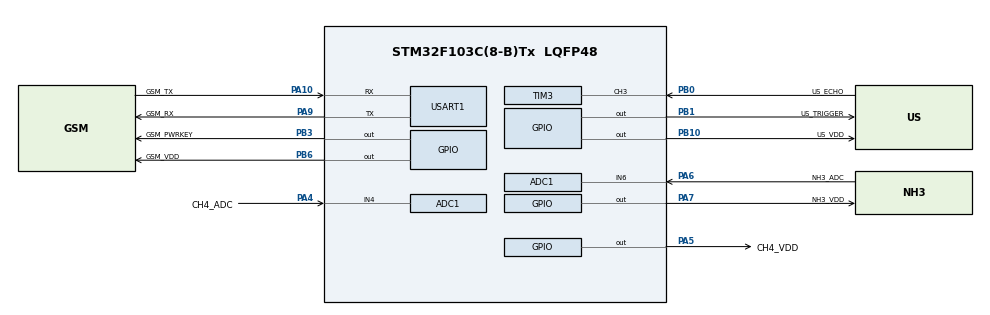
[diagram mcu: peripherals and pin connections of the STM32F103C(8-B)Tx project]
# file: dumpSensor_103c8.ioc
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ADC1.Channel-0\#ChannelRegularConversion=ADC_CHANNEL_6
ADC1.Channel-1\#ChannelRegularConversion=ADC_CHANNEL_4
ADC1.Channel-2\#ChannelRegularConversion=ADC_CHANNEL_TEMPSENSOR
ADC1.ContinuousConvMode=ENABLE
ADC1.NbrOfConversion=3
ADC1.NbrOfConversionFlag=1
ADC1.Rank-0\#ChannelRegularConversion=1
ADC1.Rank-1\#ChannelRegularConversion=2
ADC1.Rank-2\#ChannelRegularConversion=3
ADC1.SamplingTime-0\#ChannelRegularConversion=ADC_SAMPLETIME_71CYCLES_5
ADC1.SamplingTime-1\#ChannelRegularConversion=ADC_SAMPLETIME_71CYCLES_5
ADC1.SamplingTime-2\#ChannelRegularConversion=ADC_SAMPLETIME_41CYCLES_5
ADC1.master=1
Mcu.Family=STM32F1
Mcu.Name=STM32F103C(8-B)Tx
Mcu.Package=LQFP48
NVIC.PriorityGroup=NVIC_PRIORITYGROUP_4
NVIC.TIM3_IRQn=true\:0\:0\:false\:false\:true\:true\:true
NVIC.TIM4_IRQn=true\:0\:0\:false\:false\:true\:true\:true
NVIC.USART1_IRQn=true\:0\:0\:false\:false\:true\:true\:true
PA10.GPIO_Label=GSM_TX
PA10.Mode=Asynchronous
PA10.Signal=USART1_RX
PA13.Mode=Serial_Wire
PA13.Signal=SYS_JTMS-SWDIO
PA14.Mode=Serial_Wire
PA14.Signal=SYS_JTCK-SWCLK
PA4.GPIO_Label=CH4_ADC
PA4.Signal=ADCx_IN4
PA5.GPIO_Label=CH4_VDD
PA5.Signal=GPIO_Output
PA6.GPIO_Label=NH3_ADC
PA6.Signal=ADCx_IN6
PA7.GPIO_Label=NH3_VDD
PA7.Signal=GPIO_Output
PA9.GPIO_Label=GSM_RX
PA9.Mode=Asynchronous
PA9.Signal=USART1_TX
PB0.GPIO_Label=US_ECHO
PB0.Signal=S_TIM3_CH3
PB1.GPIO_Label=US_TRIGGER
PB1.Signal=GPIO_Output
PB10.GPIO_Label=US_VDD
PB10.Signal=GPIO_Output
PB3.GPIO_Label=GSM_PWRKEY
PB3.Signal=GPIO_Output
PB6.GPIO_Label=GSM_VDD
PB6.Signal=GPIO_Output
ProjectManager.HeapSize=0x200
ProjectManager.StackSize=0x400
ProjectManager.TargetToolchain=STM32CubeIDE
RCC.APB1Freq_Value=8000000
RCC.APB1TimFreq_Value=8000000
RCC.APB2Freq_Value=8000000
SH.ADCx_IN4.0=ADC1_IN4,IN4
SH.ADCx_IN6.0=ADC1_IN6,IN6
SH.S_TIM3_CH3.0=TIM3_CH3,Input_Capture3_from_TI3
TIM3.Channel-Input_Capture3_from_TI3=TIM_CHANNEL_3
TIM3.Prescaler=8-1
TIM4.Period=1000-1
TIM4.Prescaler=8-1
USART1.VirtualMode=VM_ASYNC
VP_ADC1_TempSens_Input.Mode=IN-TempSens
VP_RTC_VS_RTC_Activate.Mode=RTC_Enabled
VP_TIM4_VS_ClockSourceINT.Mode=Internal
board=custom

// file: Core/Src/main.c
/* USER CODE BEGIN Header */
/**
  ******************************************************************************
  * @file           : main.c
  * @brief          : Main program body
  ******************************************************************************
  * @attention
  *
  * <h2><center>&copy; Copyright (c) 2022 STMicroelectronics.
  * All rights reserved.</center></h2>
  *
  * This software component is licensed by ST under BSD 3-Clause license,
  * the "License"; You may not use this file except in compliance with the
  * License. You may obtain a copy of the License at:
  *                        opensource.org/licenses/BSD-3-Clause
  *
  ******************************************************************************
  */
/* USER CODE END Header */
#include "main.h"

/* USER CODE BEGIN Includes */
#include "dumpSensorManager.h"
#include "softTimer.h"

/* USER CODE END Includes */

ADC_HandleTypeDef hadc1;

RTC_HandleTypeDef hrtc;

TIM_HandleTypeDef htim3;
TIM_HandleTypeDef htim4;

UART_HandleTypeDef huart1;

void SystemClock_Config(void);
static void MX_GPIO_Init(void);
static void MX_ADC1_Init(void);
static void MX_RTC_Init(void);
static void MX_TIM3_Init(void);
static void MX_TIM4_Init(void);
static void MX_USART1_UART_Init(void);

/* USER CODE BEGIN 0 */
void HAL_TIM_PeriodElapsedCallback(TIM_HandleTypeDef *htim)
{
	softTimer_periodElapsedCallback(htim);
}

/* USER CODE END 0 */

int main(void)
{

  /* MCU Configuration--------------------------------------------------------*/

  /* Reset of all peripherals, Initializes the Flash interface and the Systick. */
  HAL_Init();

  /* Configure the system clock */
  SystemClock_Config();

  /* Initialize all configured peripherals */
  MX_GPIO_Init();
  MX_ADC1_Init();
  MX_RTC_Init();
  MX_TIM3_Init();
  MX_TIM4_Init();
  MX_USART1_UART_Init();

  /* Infinite loop */
  /* USER CODE BEGIN WHILE */
  dumpSensorManager_init();

  while (1)
  {
	  dumpSensorManager_handler();
    /* USER CODE END WHILE */

  }
}

void SystemClock_Config(void)
{
  RCC_OscInitTypeDef RCC_OscInitStruct = {0};
  RCC_ClkInitTypeDef RCC_ClkInitStruct = {0};
  RCC_PeriphCLKInitTypeDef PeriphClkInit = {0};

  /** Initializes the RCC Oscillators according to the specified parameters
  * in the RCC_OscInitTypeDef structure.
  */
  RCC_OscInitStruct.OscillatorType = RCC_OSCILLATORTYPE_HSI|RCC_OSCILLATORTYPE_LSI;
  RCC_OscInitStruct.HSIState = RCC_HSI_ON;
  RCC_OscInitStruct.HSICalibrationValue = RCC_HSICALIBRATION_DEFAULT;
  RCC_OscInitStruct.LSIState = RCC_LSI_ON;
  RCC_OscInitStruct.PLL.PLLState = RCC_PLL_NONE;
  if (HAL_RCC_OscConfig(&RCC_OscInitStruct) != HAL_OK)
  {
    Error_Handler();
  }
  /** Initializes the CPU, AHB and APB buses clocks
  */
  RCC_ClkInitStruct.ClockType = RCC_CLOCKTYPE_HCLK|RCC_CLOCKTYPE_SYSCLK
                              |RCC_CLOCKTYPE_PCLK1|RCC_CLOCKTYPE_PCLK2;
  RCC_ClkInitStruct.SYSCLKSource = RCC_SYSCLKSOURCE_HSI;
  RCC_ClkInitStruct.AHBCLKDivider = RCC_SYSCLK_DIV1;
  RCC_ClkInitStruct.APB1CLKDivider = RCC_HCLK_DIV1;
  RCC_ClkInitStruct.APB2CLKDivider = RCC_HCLK_DIV1;

  if (HAL_RCC_ClockConfig(&RCC_ClkInitStruct, FLASH_LATENCY_0) != HAL_OK)
  {
    Error_Handler();
  }
  PeriphClkInit.PeriphClockSelection = RCC_PERIPHCLK_RTC|RCC_PERIPHCLK_ADC;
  PeriphClkInit.RTCClockSelection = RCC_RTCCLKSOURCE_LSI;
  PeriphClkInit.AdcClockSelection = RCC_ADCPCLK2_DIV2;
  if (HAL_RCCEx_PeriphCLKConfig(&PeriphClkInit) != HAL_OK)
  {
    Error_Handler();
  }
}

static void MX_ADC1_Init(void)
{

  ADC_ChannelConfTypeDef sConfig = {0};

  /** Common config
  */
  hadc1.Instance = ADC1;
  hadc1.Init.ScanConvMode = ADC_SCAN_ENABLE;
  hadc1.Init.ContinuousConvMode = ENABLE;
  hadc1.Init.DiscontinuousConvMode = DISABLE;
  hadc1.Init.ExternalTrigConv = ADC_SOFTWARE_START;
  hadc1.Init.DataAlign = ADC_DATAALIGN_RIGHT;
  hadc1.Init.NbrOfConversion = 3;
  if (HAL_ADC_Init(&hadc1) != HAL_OK)
  {
    Error_Handler();
  }
  /** Configure Regular Channel
  */
  sConfig.Channel = ADC_CHANNEL_6;
  sConfig.Rank = ADC_REGULAR_RANK_1;
  sConfig.SamplingTime = ADC_SAMPLETIME_71CYCLES_5;
  if (HAL_ADC_ConfigChannel(&hadc1, &sConfig) != HAL_OK)
  {
    Error_Handler();
  }
  /** Configure Regular Channel
  */
  sConfig.Channel = ADC_CHANNEL_4;
  sConfig.Rank = ADC_REGULAR_RANK_2;
  if (HAL_ADC_ConfigChannel(&hadc1, &sConfig) != HAL_OK)
  {
    Error_Handler();
  }
  /** Configure Regular Channel
  */
  sConfig.Channel = ADC_CHANNEL_TEMPSENSOR;
  sConfig.Rank = ADC_REGULAR_RANK_3;
  sConfig.SamplingTime = ADC_SAMPLETIME_41CYCLES_5;
  if (HAL_ADC_ConfigChannel(&hadc1, &sConfig) != HAL_OK)
  {
    Error_Handler();
  }

}

static void MX_RTC_Init(void)
{

  /** Initialize RTC Only
  */
  hrtc.Instance = RTC;
  hrtc.Init.AsynchPrediv = RTC_AUTO_1_SECOND;
  hrtc.Init.OutPut = RTC_OUTPUTSOURCE_ALARM;
  if (HAL_RTC_Init(&hrtc) != HAL_OK)
  {
    Error_Handler();
  }

}

static void MX_TIM3_Init(void)
{

  TIM_MasterConfigTypeDef sMasterConfig = {0};
  TIM_IC_InitTypeDef sConfigIC = {0};

  htim3.Instance = TIM3;
  htim3.Init.Prescaler = 8-1;
  htim3.Init.CounterMode = TIM_COUNTERMODE_UP;
  htim3.Init.Period = 65535;
  htim3.Init.ClockDivision = TIM_CLOCKDIVISION_DIV1;
  htim3.Init.AutoReloadPreload = TIM_AUTORELOAD_PRELOAD_DISABLE;
  if (HAL_TIM_IC_Init(&htim3) != HAL_OK)
  {
    Error_Handler();
  }
  sMasterConfig.MasterOutputTrigger = TIM_TRGO_RESET;
  sMasterConfig.MasterSlaveMode = TIM_MASTERSLAVEMODE_DISABLE;
  if (HAL_TIMEx_MasterConfigSynchronization(&htim3, &sMasterConfig) != HAL_OK)
  {
    Error_Handler();
  }
  sConfigIC.ICPolarity = TIM_INPUTCHANNELPOLARITY_RISING;
  sConfigIC.ICSelection = TIM_ICSELECTION_DIRECTTI;
  sConfigIC.ICPrescaler = TIM_ICPSC_DIV1;
  sConfigIC.ICFilter = 0;
  if (HAL_TIM_IC_ConfigChannel(&htim3, &sConfigIC, TIM_CHANNEL_3) != HAL_OK)
  {
    Error_Handler();
  }

}

static void MX_TIM4_Init(void)
{

  TIM_ClockConfigTypeDef sClockSourceConfig = {0};
  TIM_MasterConfigTypeDef sMasterConfig = {0};

  htim4.Instance = TIM4;
  htim4.Init.Prescaler = 8-1;
  htim4.Init.CounterMode = TIM_COUNTERMODE_UP;
  htim4.Init.Period = 1000-1;
  htim4.Init.ClockDivision = TIM_CLOCKDIVISION_DIV1;
  htim4.Init.AutoReloadPreload = TIM_AUTORELOAD_PRELOAD_DISABLE;
  if (HAL_TIM_Base_Init(&htim4) != HAL_OK)
  {
    Error_Handler();
  }
  sClockSourceConfig.ClockSource = TIM_CLOCKSOURCE_INTERNAL;
  if (HAL_TIM_ConfigClockSource(&htim4, &sClockSourceConfig) != HAL_OK)
  {
    Error_Handler();
  }
  sMasterConfig.MasterOutputTrigger = TIM_TRGO_RESET;
  sMasterConfig.MasterSlaveMode = TIM_MASTERSLAVEMODE_DISABLE;
  if (HAL_TIMEx_MasterConfigSynchronization(&htim4, &sMasterConfig) != HAL_OK)
  {
    Error_Handler();
  }

}

static void MX_USART1_UART_Init(void)
{

  huart1.Instance = USART1;
  huart1.Init.BaudRate = 115200;
  huart1.Init.WordLength = UART_WORDLENGTH_8B;
  huart1.Init.StopBits = UART_STOPBITS_1;
  huart1.Init.Parity = UART_PARITY_NONE;
  huart1.Init.Mode = UART_MODE_TX_RX;
  huart1.Init.HwFlowCtl = UART_HWCONTROL_NONE;
  huart1.Init.OverSampling = UART_OVERSAMPLING_16;
  if (HAL_UART_Init(&huart1) != HAL_OK)
  {
    Error_Handler();
  }

}

static void MX_GPIO_Init(void)
{
  GPIO_InitTypeDef GPIO_InitStruct = {0};

  /* GPIO Ports Clock Enable */
  __HAL_RCC_GPIOA_CLK_ENABLE();
  __HAL_RCC_GPIOB_CLK_ENABLE();

  /*Configure GPIO pin Output Level */
  HAL_GPIO_WritePin(GPIOA, CH4_VDD_Pin|NH3_VDD_Pin, GPIO_PIN_RESET);

  /*Configure GPIO pin Output Level */
  HAL_GPIO_WritePin(GPIOB, US_TRIGGER_Pin|US_VDD_Pin|GSM_PWRKEY_Pin|GSM_VDD_Pin, GPIO_PIN_RESET);

  /*Configure GPIO pins : CH4_VDD_Pin NH3_VDD_Pin */
  GPIO_InitStruct.Pin = CH4_VDD_Pin|NH3_VDD_Pin;
  GPIO_InitStruct.Mode = GPIO_MODE_OUTPUT_PP;
  GPIO_InitStruct.Pull = GPIO_NOPULL;
  GPIO_InitStruct.Speed = GPIO_SPEED_FREQ_LOW;
  HAL_GPIO_Init(GPIOA, &GPIO_InitStruct);

  /*Configure GPIO pins : US_TRIGGER_Pin US_VDD_Pin GSM_PWRKEY_Pin GSM_VDD_Pin */
  GPIO_InitStruct.Pin = US_TRIGGER_Pin|US_VDD_Pin|GSM_PWRKEY_Pin|GSM_VDD_Pin;
  GPIO_InitStruct.Mode = GPIO_MODE_OUTPUT_PP;
  GPIO_InitStruct.Pull = GPIO_NOPULL;
  GPIO_InitStruct.Speed = GPIO_SPEED_FREQ_LOW;
  HAL_GPIO_Init(GPIOB, &GPIO_InitStruct);

}

void Error_Handler(void)
{
  __disable_irq();
  while (1)
  {
  }
}

/************************ (C) COPYRIGHT STMicroelectronics *****END OF FILE****/
